# soc register map
Vendor: litex
Registers are 32-bit, read-write, reset 0x0 unless marked. A register's access mark holds for its fields unless they carry their own. Offsets are from the block's base; lines under a group give offsets from that group; [hi:lo] are bit positions; {n}, {i} and the like mark numbered series; 'fields as' and 'values as' point back to an identical list; <NAME> marks a mode.

## Memory map
0x00000000 CTRL size 0xC
0x00000800 LEDS size 0x4

## Further device data
memoryRegions:
  CSR baseAddress=0x00000000 size=0x00010000

## CTRL
Base 0x00000000
0x00 RESET — Write a ``1`` to this register to reset the SoC.
  [0] reset
0x04 SCRATCH reset 0x12345678 — Use this register as a scratch space to verify that software read/write accesses to the Wishbone/CSR bus are working correctly. The initial reset value of 0x1234578 can be used to verify endianness.
0x08 BUS_ERRORS ro — Total number of Wishbone bus errors (timeouts) since start.

## LEDS
Base 0x00000800
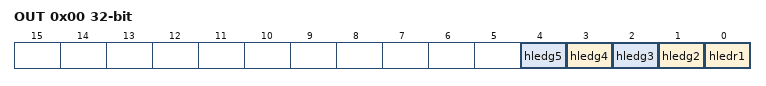
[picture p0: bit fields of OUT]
0x00 OUT
  [n-1] hledg{n} (n=2..5) — Green LED #{n} on the iCEBreaker head.
  [0] hledr1 — The center Red LED #1 on the iCEBreaker head.
